# PIC32CX2051BZ62132 register map
Vendor: Microchip Technology; Series: PIC32CXBZ62; File version: 0
CPU: CM4 r0p1, little endian, MPU, FPU, 3 interrupt priority bits, 58 interrupts
Registers are 32-bit, read-write, reset 0x0 unless marked. A register's access mark holds for its fields unless they carry their own. Offsets are from the block's base; [hi:lo] are bit positions; {n}, {i} and the like mark numbered series; 'fields as' and 'values as' point back to an identical list.

## BLE
Base 0x41012000
0x4B8 DPLL_RG1 16-bit
  [15:0] DPLL_RG1BITS
0x4BA DPLL_RG2 16-bit
  [15:0] DPLL_RG2BITS
0x1000 SPI_WR_DATA 16-bit
0x1002 SPI_REG_ADDR 16-bit
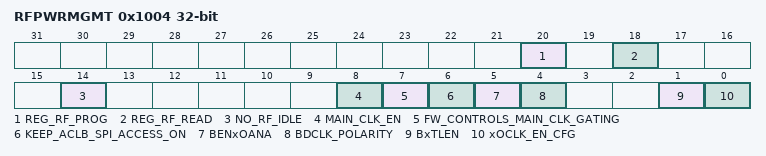
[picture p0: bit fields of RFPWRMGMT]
0x1004 RFPWRMGMT
  [20] REG_RF_PROG, [18] REG_RF_READ, [14] NO_RF_IDLE, [8] MAIN_CLK_EN, [7] FW_CONTROLS_MAIN_CLK_GATING, [6] KEEP_ACLB_SPI_ACCESS_ON, [5] BENxOANA, [4] BDCLK_POLARITY, [1] BxTLEN, [0] xOCLK_EN_CFG

## BTZBSYS — BT ZB Subsystem
Base 0x41014000
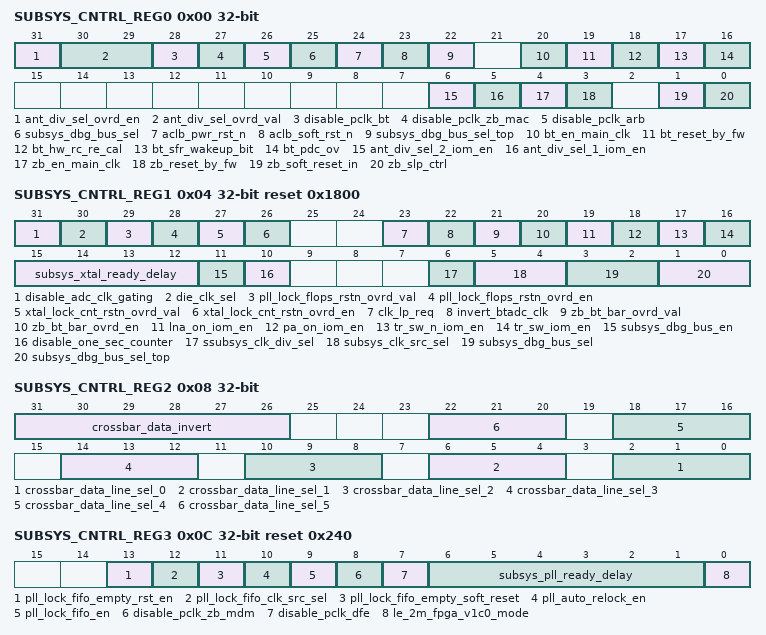
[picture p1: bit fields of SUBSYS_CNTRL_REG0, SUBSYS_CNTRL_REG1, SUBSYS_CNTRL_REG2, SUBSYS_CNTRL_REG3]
0x00 SUBSYS_CNTRL_REG0
  [31] ant_div_sel_ovrd_en, [30:29] ant_div_sel_ovrd_val, [28] disable_pclk_bt, [27] disable_pclk_zb_mac, [26] disable_pclk_arb, [25] subsys_dbg_bus_sel, [24] aclb_pwr_rst_n, [23] aclb_soft_rst_n, [22] subsys_dbg_bus_sel_top, [20] bt_en_main_clk, [19] bt_reset_by_fw, [18] bt_hw_rc_re_cal, [17] bt_sfr_wakeup_bit, [16] bt_pdc_ov, [6] ant_div_sel_2_iom_en, [5] ant_div_sel_1_iom_en, [4] zb_en_main_clk, [3] zb_reset_by_fw, [1] zb_soft_reset_in, [0] zb_slp_ctrl
0x04 SUBSYS_CNTRL_REG1 reset 0x1800
  [31] disable_adc_clk_gating
  [30] die_clk_sel
  [29] pll_lock_flops_rstn_ovrd_val
  [28] pll_lock_flops_rstn_ovrd_en
  [27] xtal_lock_cnt_rstn_ovrd_val
  [26] xtal_lock_cnt_rstn_ovrd_en
  [23] clk_lp_req
  [22] invert_btadc_clk
  [21] zb_bt_bar_ovrd_val
  [20] zb_bt_bar_ovrd_en
  [19] lna_on_iom_en
  [18] pa_on_iom_en
  [17] tr_sw_n_iom_en
  [16] tr_sw_iom_en
  [15:12] subsys_xtal_ready_delay
  [11] subsys_dbg_bus_en
  [10] disable_one_sec_counter
  [6] ssubsys_clk_div_sel — subsys_clk_div_sel
  [5:4] subsys_clk_src_sel
  [3:2] subsys_dbg_bus_sel
  [1:0] subsys_dbg_bus_sel_top
0x08 SUBSYS_CNTRL_REG2
  [31:26] crossbar_data_invert, [4n+2:4n] crossbar_data_line_sel_{n} (n=0..5)
0x0C SUBSYS_CNTRL_REG3 reset 0x240
  [13] pll_lock_fifo_empty_rst_en, [12] pll_lock_fifo_clk_src_sel, [11] pll_lock_fifo_empty_soft_reset, [10] pll_auto_relock_en, [9] pll_lock_fifo_en, [8] disable_pclk_zb_mdm, [7] disable_pclk_dfe, [6:1] subsys_pll_ready_delay, [0] le_2m_fpga_v1c0_mode
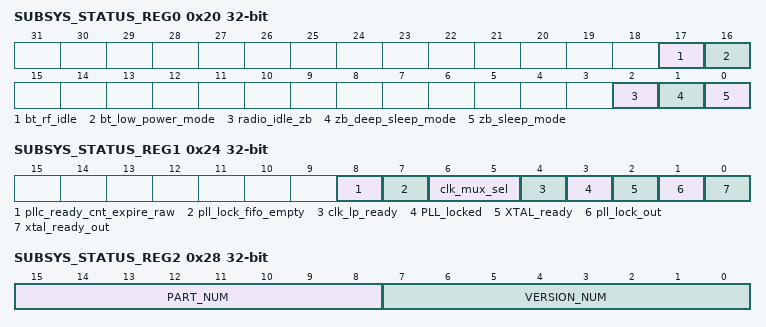
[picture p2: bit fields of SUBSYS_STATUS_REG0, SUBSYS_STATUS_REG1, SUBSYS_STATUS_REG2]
0x20 SUBSYS_STATUS_REG0 ro
  [17] bt_rf_idle, [16] bt_low_power_mode, [2] radio_idle_zb, [1] zb_deep_sleep_mode, [0] zb_sleep_mode
0x24 SUBSYS_STATUS_REG1 ro
  [8] pllc_ready_cnt_expire_raw
  [7] pll_lock_fifo_empty — XTAL_ready
  [6:5] clk_mux_sel — clk_mux_sel0
  [4] clk_lp_ready
  [3] PLL_locked
  [2] XTAL_ready
  [1] pll_lock_out
  [0] xtal_ready_out
0x28 SUBSYS_STATUS_REG2 ro
  [15:8] PART_NUM, [7:0] VERSION_NUM

## CCL — Configurable Custom Logic
Base 0x42001800
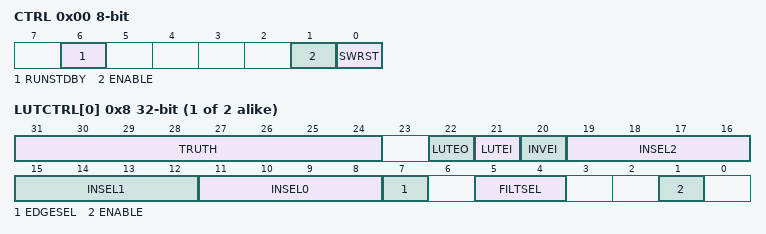
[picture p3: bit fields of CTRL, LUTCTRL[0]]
0x00 CTRL 8-bit — Control
  [6] RUNSTDBY — Run in Standby
    0=DISABLE (Generic clock is not required in standby sleep mode); 1=ENABLE (Generic clock is required in standby sleep mode)
  [1] ENABLE
    0=DISABLE (The peripheral is disabled); 1=ENABLE (The peripheral is enabled)
  [0] SWRST — Software Reset
    0=DISABLE (The peripheral is not reset); 1=ENABLE (The peripheral is reset)
{0x4+i} SEQCTRL[{i}] (i=0..0) 8-bit — SEQ Control x
  [3:0] SEQSEL — Sequential Selection
    0=DISABLE (Sequential logic is disabled); 1=DFF (D flip flop); 2=JK (JK flip flop); 3=LATCH (D latch); 4=RS (RS latch)
{0x8+4i} LUTCTRL[{i}] (i=0..1) — LUT Control x
  [31:24] TRUTH — Truth Value
  [22] LUTEO — LUT Event Output Enable
    0=DISABLE (LUT event output is disabled); 1=ENABLE (LUT event output is enabled)
  [21] LUTEI — LUT Event Input Enable
    0=DISABLE (LUT incoming event is disabled); 1=ENABLE (LUT incoming event is enabled)
  [20] INVEI — Inverted Event Input Enable
    0=DISABLE (Incoming event is not inverted); 1=ENABLE (Incoming event is inverted)
  [19:16] INSEL2 — Input Selection 2
    0=MASK (Masked input); 1=FEEDBACK (Feedback input source); 2=LINK (Linked LUT input source); 3=EVENT (Event input source); 4=IO (I/O pin input source); 5=AC (AC input source); 6=TC (TC input source); 7=ALTTC (Alternate TC input source); 8=TCC (TCC input source); 9=SERCOM (SERCOM input source)
  [15:12] INSEL1 — Input Selection 1
    values as INSEL2
  [11:8] INSEL0 — Input Selection 0
    values as INSEL2
  [7] EDGESEL — Edge Selection
    0=DISABLE (Edge detector is disabled); 1=ENABLE (Edge detector is enabled)
  [5:4] FILTSEL — Filter Selection
    0=DISABLE (Filter disabled); 1=SYNCH (Synchronizer enabled); 2=FILTER (Filter enabled)
  [1] ENABLE — LUT Enable
    0=DISABLE (LUT block is disabled); 1=ENABLE (LUT block is enabled)

## Notices in the file
Copyright (c) 2026 Microchip Technology Inc.
SPDX-License-Identifier: Apache-2.0
Licensed under the Apache License, Version 2.0 (the "License");
you may not use this file except in compliance with the License.
You may obtain a copy of the License at
http://www.apache.org/licenses/LICENSE-2.0
Unless required by applicable law or agreed to in writing, software
distributed under the License is distributed on an "AS IS" BASIS,
WITHOUT WARRANTIES OR CONDITIONS OF ANY KIND, either express or implied.
See the License for the specific language governing permissions and
limitations under the License.
